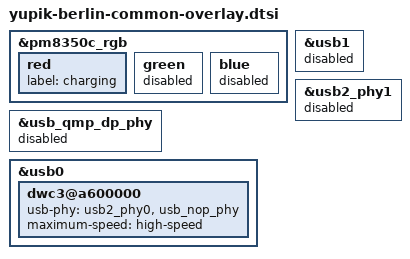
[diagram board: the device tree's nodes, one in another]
/* Copyright (c) 2021, The Linux Foundation. All rights reserved.
 *
 * This program is free software; you can redistribute it and/or modify
 * it under the terms of the GNU General Public License version 2 and
 * only version 2 as published by the Free Software Foundation.
 *
 * This program is distributed in the hope that it will be useful,
 * but WITHOUT ANY WARRANTY; without even the implied warranty of
 * MERCHANTABILITY or FITNESS FOR A PARTICULAR PURPOSE.  See the
 * GNU General Public License for more details.
 */

#include "yupik-moto-common-overlay.dtsi"

&pm8350c_rgb {
	red {
		label = "charging";
	};
	green {
		status = "disabled";
	};
	blue {
		status = "disabled";
	};
};

&usb_qmp_dp_phy {
	status = "disabled";
};

&usb1 {
	status = "disabled";
};

&usb2_phy1 {
	status = "disabled";
};

&usb0 {
	dwc3@a600000 {
		usb-phy = <&usb2_phy0>, <&usb_nop_phy>;
		maximum-speed = "high-speed";
	};
};
